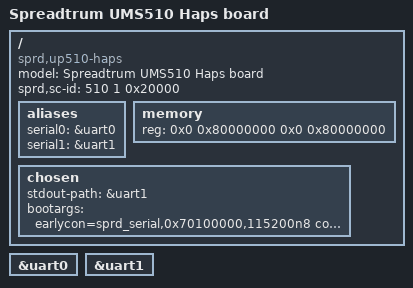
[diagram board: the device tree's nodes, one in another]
// SPDX-License-Identifier: (GPL-2.0+ OR MIT)
/*
 * Spreadtrum Sharkl5 platform DTS file
 *
 * Copyright (C) 2018, Spreadtrum Communications Inc.
 */

/dts-v1/;

#include "ums510.dtsi"

/ {
	model = "Spreadtrum UMS510 Haps board";

	compatible = "sprd,up510-haps", "sprd,ums510";

	sprd,sc-id = <510 1 0x20000>;

	aliases {
		serial0 = &uart0;
		serial1 = &uart1;
	};

	memory {
		device_type = "memory";
		reg = <0x0 0x80000000 0x0 0x80000000>;
	};

	chosen {
		stdout-path = &uart1;
		bootargs = "earlycon=sprd_serial,0x70100000,115200n8 console=ttyS1,115200n8 loglevel=11";
	};
};

&uart0 {
	status = "okay";
};

&uart1 {
	status = "okay";
};
